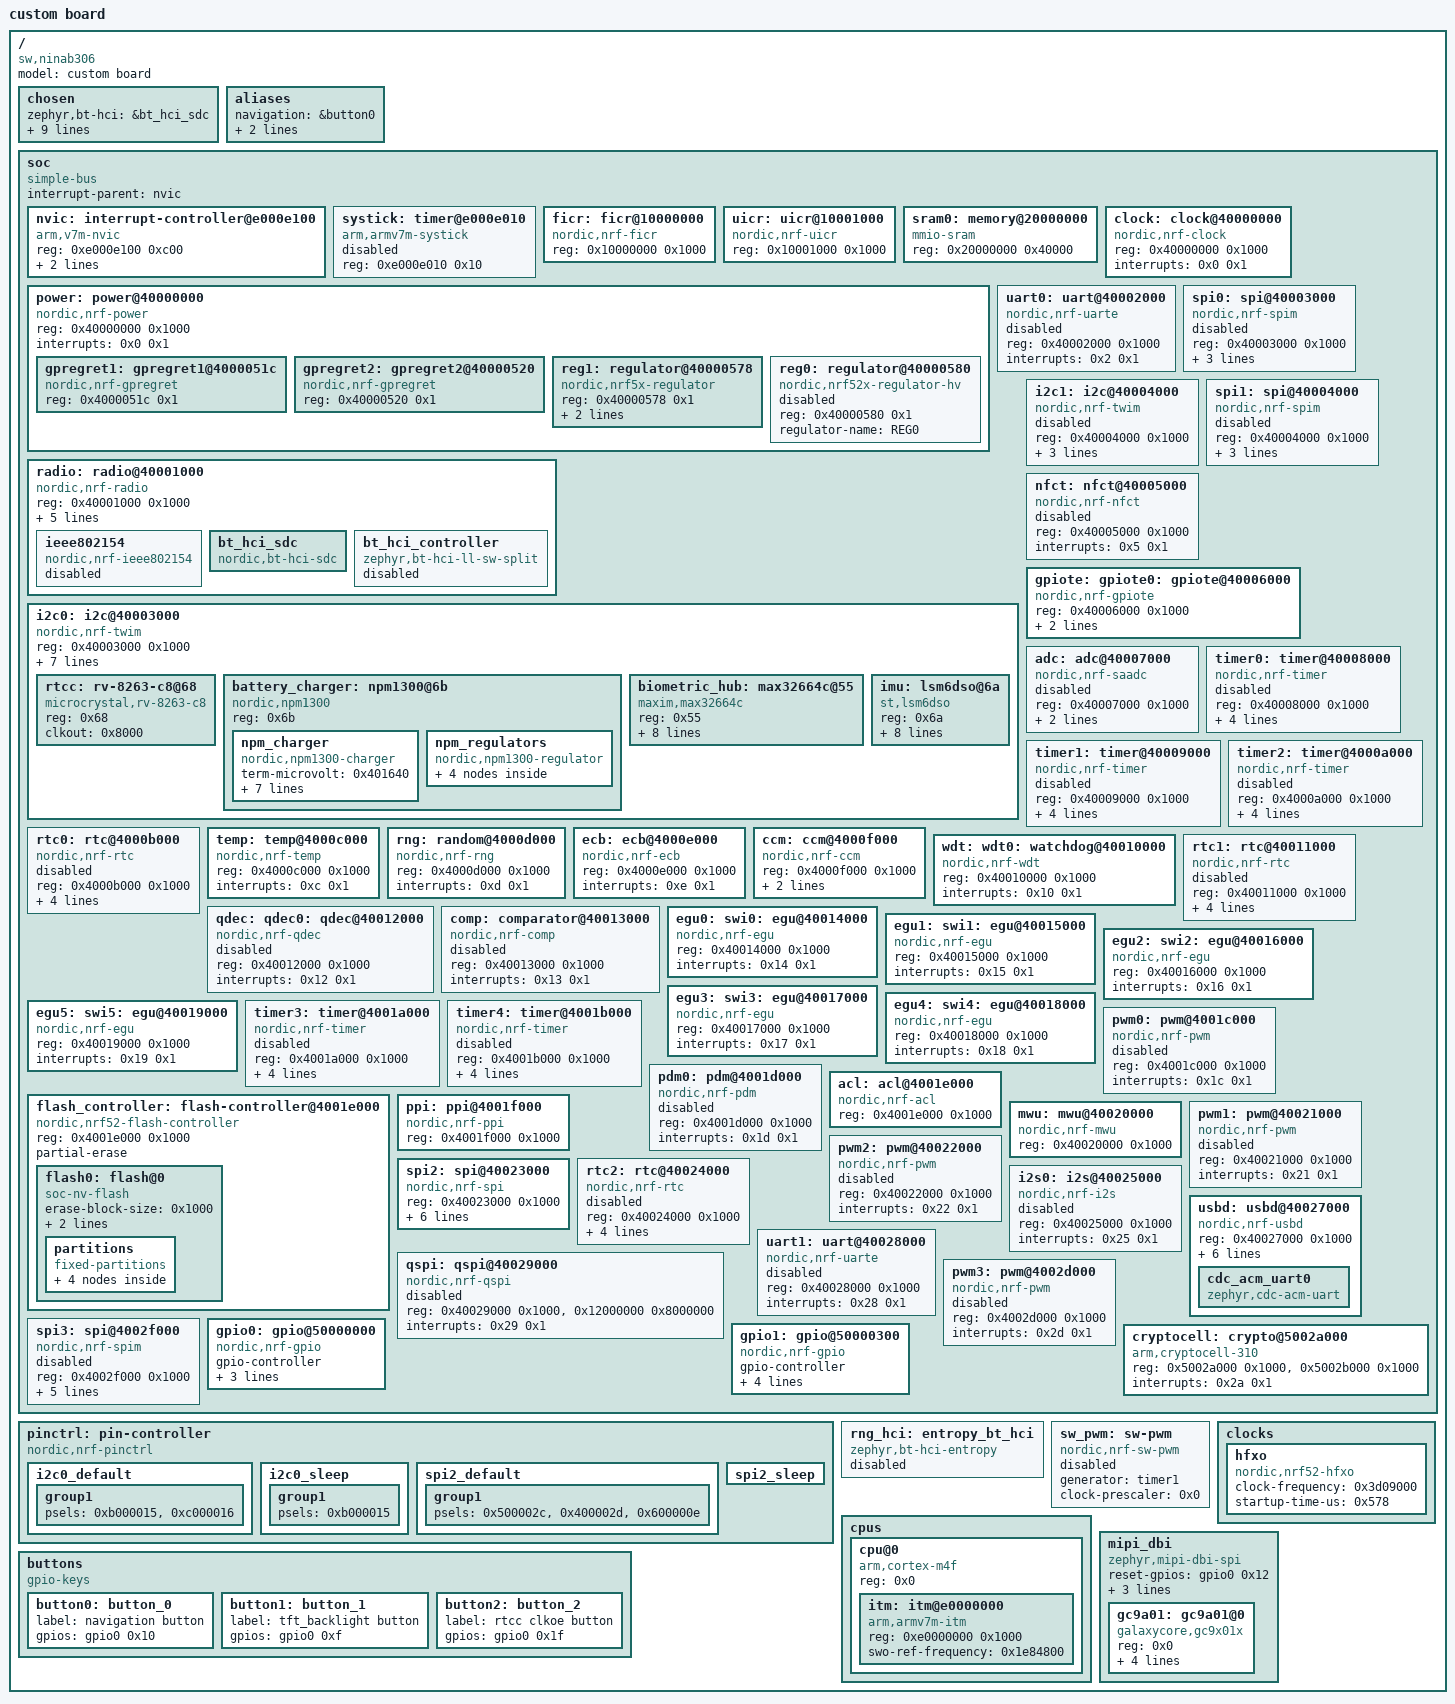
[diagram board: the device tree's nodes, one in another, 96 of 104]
/dts-v1/;

/* node '/' defined in zephyr/dts/common/skeleton.dtsi:9 */
/ {
	#address-cells = < 0x1 >;   /* in zephyr/dts/common/skeleton.dtsi:10 */
	#size-cells = < 0x1 >;      /* in zephyr/dts/common/skeleton.dtsi:11 */
	model = "custom board";     /* in ../../Documents/watch_project/nrf_firmware/boards/sw/ninab306/ninab306.dts:6 */
	compatible = "sw,ninab306"; /* in ../../Documents/watch_project/nrf_firmware/boards/sw/ninab306/ninab306.dts:7 */

	/* node '/chosen' defined in zephyr/dts/common/skeleton.dtsi:12 */
	chosen {
		zephyr,bt-hci = &bt_hci_sdc;                 /* in zephyr/dts/arm/nordic/nrf52840.dtsi:14 */
		zephyr,entropy = &cryptocell;                /* in zephyr/dts/arm/nordic/nrf52840.dtsi:15 */
		zephyr,flash-controller = &flash_controller; /* in zephyr/dts/arm/nordic/nrf52840.dtsi:16 */
		zephyr,sram = &sram0;                        /* in ../../Documents/watch_project/nrf_firmware/boards/sw/ninab306/ninab306.dts:10 */
		zephyr,flash = &flash0;                      /* in ../../Documents/watch_project/nrf_firmware/boards/sw/ninab306/ninab306.dts:11 */
		zephyr,code-partition = &slot0_partition;    /* in ../../Documents/watch_project/nrf_firmware/boards/sw/ninab306/ninab306.dts:12 */
		zephyr,console = &cdc_acm_uart0;             /* in ../../Documents/watch_project/nrf_firmware/boards/sw/ninab306/ninab306.dts:13 */
		zephyr,shell-uart = &cdc_acm_uart0;          /* in ../../Documents/watch_project/nrf_firmware/boards/sw/ninab306/ninab306.dts:14 */
		zephyr,bt-uart = &cdc_acm_uart0;             /* in ../../Documents/watch_project/nrf_firmware/boards/sw/ninab306/ninab306.dts:15 */
		zephyr,display = &gc9a01;                    /* in ../../Documents/watch_project/firmware/ninab306_nrf52840.overlay:18 */
	};

	/* node '/aliases' defined in zephyr/dts/common/skeleton.dtsi:13 */
	aliases {
		navigation = &button0; /* in ../../Documents/watch_project/firmware/ninab306_nrf52840.overlay:50 */
		bcklight = &button1;   /* in ../../Documents/watch_project/firmware/ninab306_nrf52840.overlay:51 */
		clkoe = &button2;      /* in ../../Documents/watch_project/firmware/ninab306_nrf52840.overlay:52 */
	};

	/* node '/soc' defined in zephyr/dts/arm/armv7-m.dtsi:6 */
	soc {
		#address-cells = < 0x1 >;     /* in zephyr/dts/arm/armv7-m.dtsi:7 */
		#size-cells = < 0x1 >;        /* in zephyr/dts/arm/armv7-m.dtsi:8 */
		interrupt-parent = < &nvic >; /* in zephyr/dts/arm/armv7-m.dtsi:10 */
		ranges;                       /* in zephyr/dts/arm/armv7-m.dtsi:11 */
		compatible = "simple-bus";    /* in zephyr/dts/arm/nordic/nrf52840_qiaa.dtsi:29 */

		/* node '/soc/interrupt-controller@e000e100' defined in zephyr/dts/arm/armv7-m.dtsi:13 */
		nvic: interrupt-controller@e000e100 {
			#address-cells = < 0x1 >;            /* in zephyr/dts/arm/armv7-m.dtsi:14 */
			compatible = "arm,v7m-nvic";         /* in zephyr/dts/arm/armv7-m.dtsi:15 */
			reg = < 0xe000e100 0xc00 >;          /* in zephyr/dts/arm/armv7-m.dtsi:16 */
			interrupt-controller;                /* in zephyr/dts/arm/armv7-m.dtsi:17 */
			#interrupt-cells = < 0x2 >;          /* in zephyr/dts/arm/armv7-m.dtsi:18 */
			arm,num-irq-priority-bits = < 0x3 >; /* in zephyr/dts/arm/nordic/nrf52840.dtsi:585 */
			phandle = < 0x1 >;                   /* in zephyr/dts/arm/armv7-m.dtsi:10 */
		};

		/* node '/soc/timer@e000e010' defined in zephyr/dts/arm/armv7-m.dtsi:21 */
		systick: timer@e000e010 {
			compatible = "arm,armv7m-systick"; /* in zephyr/dts/arm/armv7-m.dtsi:22 */
			reg = < 0xe000e010 0x10 >;         /* in zephyr/dts/arm/armv7-m.dtsi:23 */
			status = "disabled";               /* in zephyr/dts/arm/nordic/nrf52840.dtsi:590 */
		};

		/* node '/soc/ficr@10000000' defined in zephyr/dts/arm/nordic/nrf52840.dtsi:48 */
		ficr: ficr@10000000 {
			compatible = "nordic,nrf-ficr"; /* in zephyr/dts/arm/nordic/nrf52840.dtsi:49 */
			reg = < 0x10000000 0x1000 >;    /* in zephyr/dts/arm/nordic/nrf52840.dtsi:50 */
			#nordic,ficr-cells = < 0x1 >;   /* in zephyr/dts/arm/nordic/nrf52840.dtsi:51 */
			status = "okay";                /* in zephyr/dts/arm/nordic/nrf52840.dtsi:52 */
		};

		/* node '/soc/uicr@10001000' defined in zephyr/dts/arm/nordic/nrf52840.dtsi:55 */
		uicr: uicr@10001000 {
			compatible = "nordic,nrf-uicr"; /* in zephyr/dts/arm/nordic/nrf52840.dtsi:56 */
			reg = < 0x10001000 0x1000 >;    /* in zephyr/dts/arm/nordic/nrf52840.dtsi:57 */
			status = "okay";                /* in zephyr/dts/arm/nordic/nrf52840.dtsi:58 */
		};

		/* node '/soc/memory@20000000' defined in zephyr/dts/arm/nordic/nrf52840.dtsi:61 */
		sram0: memory@20000000 {
			compatible = "mmio-sram";     /* in zephyr/dts/arm/nordic/nrf52840.dtsi:62 */
			reg = < 0x20000000 0x40000 >; /* in zephyr/dts/arm/nordic/nrf52840_qiaa.dtsi:15 */
		};

		/* node '/soc/clock@40000000' defined in zephyr/dts/arm/nordic/nrf52840.dtsi:65 */
		clock: clock@40000000 {
			compatible = "nordic,nrf-clock"; /* in zephyr/dts/arm/nordic/nrf52840.dtsi:66 */
			reg = < 0x40000000 0x1000 >;     /* in zephyr/dts/arm/nordic/nrf52840.dtsi:67 */
			interrupts = < 0x0 0x1 >;        /* in zephyr/dts/arm/nordic/nrf52840.dtsi:68 */
			status = "okay";                 /* in zephyr/dts/arm/nordic/nrf52840.dtsi:69 */
		};

		/* node '/soc/power@40000000' defined in zephyr/dts/arm/nordic/nrf52840.dtsi:72 */
		power: power@40000000 {
			compatible = "nordic,nrf-power"; /* in zephyr/dts/arm/nordic/nrf52840.dtsi:73 */
			reg = < 0x40000000 0x1000 >;     /* in zephyr/dts/arm/nordic/nrf52840.dtsi:74 */
			interrupts = < 0x0 0x1 >;        /* in zephyr/dts/arm/nordic/nrf52840.dtsi:75 */
			status = "okay";                 /* in zephyr/dts/arm/nordic/nrf52840.dtsi:76 */
			#address-cells = < 0x1 >;        /* in zephyr/dts/arm/nordic/nrf52840.dtsi:77 */
			#size-cells = < 0x1 >;           /* in zephyr/dts/arm/nordic/nrf52840.dtsi:78 */

			/* node '/soc/power@40000000/gpregret1@4000051c' defined in zephyr/dts/arm/nordic/nrf52840.dtsi:80 */
			gpregret1: gpregret1@4000051c {
				#address-cells = < 0x1 >;           /* in zephyr/dts/arm/nordic/nrf52840.dtsi:81 */
				#size-cells = < 0x1 >;              /* in zephyr/dts/arm/nordic/nrf52840.dtsi:82 */
				compatible = "nordic,nrf-gpregret"; /* in zephyr/dts/arm/nordic/nrf52840.dtsi:83 */
				reg = < 0x4000051c 0x1 >;           /* in zephyr/dts/arm/nordic/nrf52840.dtsi:84 */
				status = "okay";                    /* in zephyr/dts/arm/nordic/nrf52840.dtsi:85 */
			};

			/* node '/soc/power@40000000/gpregret2@40000520' defined in zephyr/dts/arm/nordic/nrf52840.dtsi:88 */
			gpregret2: gpregret2@40000520 {
				#address-cells = < 0x1 >;           /* in zephyr/dts/arm/nordic/nrf52840.dtsi:89 */
				#size-cells = < 0x1 >;              /* in zephyr/dts/arm/nordic/nrf52840.dtsi:90 */
				compatible = "nordic,nrf-gpregret"; /* in zephyr/dts/arm/nordic/nrf52840.dtsi:91 */
				reg = < 0x40000520 0x1 >;           /* in zephyr/dts/arm/nordic/nrf52840.dtsi:92 */
				status = "okay";                    /* in zephyr/dts/arm/nordic/nrf52840.dtsi:93 */
			};

			/* node '/soc/power@40000000/regulator@40000578' defined in zephyr/dts/arm/nordic/nrf52840.dtsi:96 */
			reg1: regulator@40000578 {
				compatible = "nordic,nrf5x-regulator"; /* in zephyr/dts/arm/nordic/nrf52840.dtsi:97 */
				reg = < 0x40000578 0x1 >;              /* in zephyr/dts/arm/nordic/nrf52840.dtsi:98 */
				regulator-name = "REG1";               /* in zephyr/dts/arm/nordic/nrf52840.dtsi:99 */
				regulator-initial-mode = < 0x0 >;      /* in zephyr/dts/arm/nordic/nrf52840.dtsi:100 */
			};

			/* node '/soc/power@40000000/regulator@40000580' defined in zephyr/dts/arm/nordic/nrf52840_qiaa.dtsi:19 */
			reg0: regulator@40000580 {
				compatible = "nordic,nrf52x-regulator-hv"; /* in zephyr/dts/arm/nordic/nrf52840_qiaa.dtsi:20 */
				reg = < 0x40000580 0x1 >;                  /* in zephyr/dts/arm/nordic/nrf52840_qiaa.dtsi:21 */
				regulator-name = "REG0";                   /* in zephyr/dts/arm/nordic/nrf52840_qiaa.dtsi:22 */
				status = "disabled";                       /* in zephyr/dts/arm/nordic/nrf52840_qiaa.dtsi:23 */
			};
		};

		/* node '/soc/radio@40001000' defined in zephyr/dts/arm/nordic/nrf52840.dtsi:104 */
		radio: radio@40001000 {
			compatible = "nordic,nrf-radio"; /* in zephyr/dts/arm/nordic/nrf52840.dtsi:105 */
			reg = < 0x40001000 0x1000 >;     /* in zephyr/dts/arm/nordic/nrf52840.dtsi:106 */
			interrupts = < 0x1 0x1 >;        /* in zephyr/dts/arm/nordic/nrf52840.dtsi:107 */
			status = "okay";                 /* in zephyr/dts/arm/nordic/nrf52840.dtsi:108 */
			ieee802154-supported;            /* in zephyr/dts/arm/nordic/nrf52840.dtsi:109 */
			ble-2mbps-supported;             /* in zephyr/dts/arm/nordic/nrf52840.dtsi:110 */
			ble-coded-phy-supported;         /* in zephyr/dts/arm/nordic/nrf52840.dtsi:111 */
			tx-high-power-supported;         /* in zephyr/dts/arm/nordic/nrf52840.dtsi:112 */

			/* node '/soc/radio@40001000/ieee802154' defined in zephyr/dts/arm/nordic/nrf52840.dtsi:114 */
			ieee802154: ieee802154 {
				compatible = "nordic,nrf-ieee802154"; /* in zephyr/dts/arm/nordic/nrf52840.dtsi:115 */
				status = "disabled";                  /* in zephyr/dts/arm/nordic/nrf52840.dtsi:116 */
			};

			/* node '/soc/radio@40001000/bt_hci_sdc' defined in zephyr/dts/arm/nordic/nrf52840.dtsi:119 */
			bt_hci_sdc: bt_hci_sdc {
				compatible = "nordic,bt-hci-sdc"; /* in zephyr/dts/arm/nordic/nrf52840.dtsi:120 */
				status = "okay";                  /* in zephyr/dts/arm/nordic/nrf52840.dtsi:121 */
			};

			/* node '/soc/radio@40001000/bt_hci_controller' defined in zephyr/dts/arm/nordic/nrf52840.dtsi:123 */
			bt_hci_controller: bt_hci_controller {
				compatible = "zephyr,bt-hci-ll-sw-split"; /* in zephyr/dts/arm/nordic/nrf52840.dtsi:124 */
				status = "disabled";                      /* in zephyr/dts/arm/nordic/nrf52840.dtsi:125 */
			};
		};

		/* node '/soc/uart@40002000' defined in zephyr/dts/arm/nordic/nrf52840.dtsi:129 */
		uart0: uart@40002000 {
			compatible = "nordic,nrf-uarte"; /* in zephyr/dts/arm/nordic/nrf52840.dtsi:132 */
			reg = < 0x40002000 0x1000 >;     /* in zephyr/dts/arm/nordic/nrf52840.dtsi:133 */
			interrupts = < 0x2 0x1 >;        /* in zephyr/dts/arm/nordic/nrf52840.dtsi:134 */
			status = "disabled";             /* in zephyr/dts/arm/nordic/nrf52840.dtsi:135 */
		};

		/* node '/soc/i2c@40003000' defined in zephyr/dts/arm/nordic/nrf52840.dtsi:138 */
		i2c0: i2c@40003000 {
			compatible = "nordic,nrf-twim"; /* in zephyr/dts/arm/nordic/nrf52840.dtsi:146 */
			#address-cells = < 0x1 >;       /* in zephyr/dts/arm/nordic/nrf52840.dtsi:147 */
			#size-cells = < 0x0 >;          /* in zephyr/dts/arm/nordic/nrf52840.dtsi:148 */
			reg = < 0x40003000 0x1000 >;    /* in zephyr/dts/arm/nordic/nrf52840.dtsi:149 */
			interrupts = < 0x3 0x1 >;       /* in zephyr/dts/arm/nordic/nrf52840.dtsi:150 */
			easydma-maxcnt-bits = < 0x10 >; /* in zephyr/dts/arm/nordic/nrf52840.dtsi:151 */
			zephyr,pm-device-runtime-auto;  /* in zephyr/dts/arm/nordic/nrf52840.dtsi:153 */
			status = "okay";                /* in ../../Documents/watch_project/nrf_firmware/boards/sw/ninab306/ninab306.dts:66 */
			pinctrl-0 = < &i2c0_default >;  /* in ../../Documents/watch_project/nrf_firmware/boards/sw/ninab306/ninab306.dts:67 */
			pinctrl-1 = < &i2c0_sleep >;    /* in ../../Documents/watch_project/nrf_firmware/boards/sw/ninab306/ninab306.dts:68 */
			pinctrl-names = "default",
			                "sleep";        /* in ../../Documents/watch_project/nrf_firmware/boards/sw/ninab306/ninab306.dts:69 */
			clock-frequency = < 0x61a80 >;  /* in ../../Documents/watch_project/nrf_firmware/boards/sw/ninab306/ninab306.dts:70 */
			zephyr,deferred-init;           /* in ../../Documents/watch_project/nrf_firmware/boards/sw/ninab306/ninab306.dts:130 */

			/* node '/soc/i2c@40003000/rv-8263-c8@68' defined in ../../Documents/watch_project/nrf_firmware/boards/sw/ninab306/ninab306.dts:72 */
			rtcc: rv-8263-c8@68 {
				compatible = "microcrystal,rv-8263-c8"; /* in ../../Documents/watch_project/nrf_firmware/boards/sw/ninab306/ninab306.dts:73 */
				reg = < 0x68 >;                         /* in ../../Documents/watch_project/nrf_firmware/boards/sw/ninab306/ninab306.dts:74 */
				clkout = < 0x8000 >;                    /* in ../../Documents/watch_project/nrf_firmware/boards/sw/ninab306/ninab306.dts:75 */
				status = "okay";                        /* in ../../Documents/watch_project/nrf_firmware/boards/sw/ninab306/ninab306.dts:76 */
			};

			/* node '/soc/i2c@40003000/npm1300@6b' defined in ../../Documents/watch_project/nrf_firmware/boards/sw/ninab306/ninab306.dts:79 */
			battery_charger: npm1300@6b {
				compatible = "nordic,npm1300"; /* in ../../Documents/watch_project/nrf_firmware/boards/sw/ninab306/ninab306.dts:80 */
				reg = < 0x6b >;                /* in ../../Documents/watch_project/nrf_firmware/boards/sw/ninab306/ninab306.dts:81 */

				/* node '/soc/i2c@40003000/npm1300@6b/npm_charger' defined in ../../Documents/watch_project/nrf_firmware/boards/sw/ninab306/ninab306.dts:83 */
				npm_charger {
					compatible = "nordic,npm1300-charger"; /* in ../../Documents/watch_project/nrf_firmware/boards/sw/ninab306/ninab306.dts:84 */
					status = "okay";                       /* in ../../Documents/watch_project/nrf_firmware/boards/sw/ninab306/ninab306.dts:85 */
					term-microvolt = < 0x401640 >;         /* in ../../Documents/watch_project/nrf_firmware/boards/sw/ninab306/ninab306.dts:86 */
					current-microamp = < 0x7a120 >;        /* in ../../Documents/watch_project/nrf_firmware/boards/sw/ninab306/ninab306.dts:87 */
					dischg-limit-microamp = < 0xf4240 >;   /* in ../../Documents/watch_project/nrf_firmware/boards/sw/ninab306/ninab306.dts:88 */
					term-current-percent = < 0x14 >;       /* in ../../Documents/watch_project/nrf_firmware/boards/sw/ninab306/ninab306.dts:89 */
					vbus-limit-microamp = < 0x16e360 >;    /* in ../../Documents/watch_project/nrf_firmware/boards/sw/ninab306/ninab306.dts:90 */
					thermistor-ohms = < 0x0 >;             /* in ../../Documents/watch_project/nrf_firmware/boards/sw/ninab306/ninab306.dts:91 */
					thermistor-beta = < 0x0 >;             /* in ../../Documents/watch_project/nrf_firmware/boards/sw/ninab306/ninab306.dts:92 */
					charging-enable;                       /* in ../../Documents/watch_project/nrf_firmware/boards/sw/ninab306/ninab306.dts:93 */
				};

				/* node '/soc/i2c@40003000/npm1300@6b/npm_regulators' defined in ../../Documents/watch_project/nrf_firmware/boards/sw/ninab306/ninab306.dts:97 */
				npm_regulators {
					compatible = "nordic,npm1300-regulator"; /* in ../../Documents/watch_project/nrf_firmware/boards/sw/ninab306/ninab306.dts:98 */

					/* node '/soc/i2c@40003000/npm1300@6b/npm_regulators/BUCK1' defined in ../../Documents/watch_project/nrf_firmware/boards/sw/ninab306/ninab306.dts:100 */
					BUCK1 {
						regulator-boot-on; /* in ../../Documents/watch_project/nrf_firmware/boards/sw/ninab306/ninab306.dts:101 */
					};

					/* node '/soc/i2c@40003000/npm1300@6b/npm_regulators/BUCK2' defined in ../../Documents/watch_project/nrf_firmware/boards/sw/ninab306/ninab306.dts:104 */
					BUCK2 {
						regulator-boot-off; /* in ../../Documents/watch_project/nrf_firmware/boards/sw/ninab306/ninab306.dts:105 */
					};

					/* node '/soc/i2c@40003000/npm1300@6b/npm_regulators/LDO1' defined in ../../Documents/watch_project/nrf_firmware/boards/sw/ninab306/ninab306.dts:107 */
					LDO1 {
						regulator-boot-off; /* in ../../Documents/watch_project/nrf_firmware/boards/sw/ninab306/ninab306.dts:108 */
					};

					/* node '/soc/i2c@40003000/npm1300@6b/npm_regulators/LDO2' defined in ../../Documents/watch_project/nrf_firmware/boards/sw/ninab306/ninab306.dts:110 */
					LDO2 {
						regulator-boot-off; /* in ../../Documents/watch_project/nrf_firmware/boards/sw/ninab306/ninab306.dts:111 */
					};
				};
			};

			/* node '/soc/i2c@40003000/max32664c@55' defined in ../../Documents/watch_project/nrf_firmware/boards/sw/ninab306/ninab306.dts:116 */
			biometric_hub: max32664c@55 {
				compatible = "maxim,max32664c";    /* in ../../Documents/watch_project/nrf_firmware/boards/sw/ninab306/ninab306.dts:117 */
				reg = < 0x55 >;                    /* in ../../Documents/watch_project/nrf_firmware/boards/sw/ninab306/ninab306.dts:118 */
				status = "okay";                   /* in ../../Documents/watch_project/nrf_firmware/boards/sw/ninab306/ninab306.dts:119 */
				reset-gpios = < &gpio0 0x19 0x0 >; /* in ../../Documents/watch_project/nrf_firmware/boards/sw/ninab306/ninab306.dts:120 */
				mfio-gpios = < &gpio0 0x18 0x0 >;  /* in ../../Documents/watch_project/nrf_firmware/boards/sw/ninab306/ninab306.dts:121 */
				hr-config = [ 00 01 ];             /* in ../../Documents/watch_project/nrf_firmware/boards/sw/ninab306/ninab306.dts:122 */
				spo2-config = [ 11 21 ];           /* in ../../Documents/watch_project/nrf_firmware/boards/sw/ninab306/ninab306.dts:123 */
				led-current = [ 3F 3F 3F ];        /* in ../../Documents/watch_project/nrf_firmware/boards/sw/ninab306/ninab306.dts:124 */
				min-sampling-rate = < 0x190 >;     /* in ../../Documents/watch_project/nrf_firmware/boards/sw/ninab306/ninab306.dts:125 */
				max-sampling-rate = < 0x190 >;     /* in ../../Documents/watch_project/nrf_firmware/boards/sw/ninab306/ninab306.dts:126 */
				use-max86141;                      /* in ../../Documents/watch_project/nrf_firmware/boards/sw/ninab306/ninab306.dts:127 */
			};

			/* node '/soc/i2c@40003000/lsm6dso@6a' defined in ../../Documents/watch_project/nrf_firmware/boards/sw/ninab306/ninab306.dts:131 */
			imu: lsm6dso@6a {
				compatible = "st,lsm6dso"; /* in ../../Documents/watch_project/nrf_firmware/boards/sw/ninab306/ninab306.dts:132 */
				reg = < 0x6a >;            /* in ../../Documents/watch_project/nrf_firmware/boards/sw/ninab306/ninab306.dts:133 */
				drdy-pulsed;               /* in ../../Documents/watch_project/nrf_firmware/boards/sw/ninab306/ninab306.dts:134 */
				accel-odr = < 0x1 >;       /* in ../../Documents/watch_project/nrf_firmware/boards/sw/ninab306/ninab306.dts:135 */
				accel-pm = < 0x2 >;        /* in ../../Documents/watch_project/nrf_firmware/boards/sw/ninab306/ninab306.dts:136 */
				accel-range = < 0x3 >;     /* in ../../Documents/watch_project/nrf_firmware/boards/sw/ninab306/ninab306.dts:137 */
				gyro-odr = < 0x1 >;        /* in ../../Documents/watch_project/nrf_firmware/boards/sw/ninab306/ninab306.dts:138 */
				gyro-pm = < 0x1 >;         /* in ../../Documents/watch_project/nrf_firmware/boards/sw/ninab306/ninab306.dts:139 */
				gyro-range = < 0x6 >;      /* in ../../Documents/watch_project/nrf_firmware/boards/sw/ninab306/ninab306.dts:140 */
				int-pin = < 0x2 >;         /* in ../../Documents/watch_project/nrf_firmware/boards/sw/ninab306/ninab306.dts:141 */
				status = "okay";           /* in ../../Documents/watch_project/nrf_firmware/boards/sw/ninab306/ninab306.dts:142 */
			};
		};

		/* node '/soc/spi@40003000' defined in zephyr/dts/arm/nordic/nrf52840.dtsi:156 */
		spi0: spi@40003000 {
			compatible = "nordic,nrf-spim"; /* in zephyr/dts/arm/nordic/nrf52840.dtsi:164 */
			#address-cells = < 0x1 >;       /* in zephyr/dts/arm/nordic/nrf52840.dtsi:165 */
			#size-cells = < 0x0 >;          /* in zephyr/dts/arm/nordic/nrf52840.dtsi:166 */
			reg = < 0x40003000 0x1000 >;    /* in zephyr/dts/arm/nordic/nrf52840.dtsi:167 */
			interrupts = < 0x3 0x1 >;       /* in zephyr/dts/arm/nordic/nrf52840.dtsi:168 */
			max-frequency = < 0x7a1200 >;   /* in zephyr/dts/arm/nordic/nrf52840.dtsi:169 */
			easydma-maxcnt-bits = < 0x10 >; /* in zephyr/dts/arm/nordic/nrf52840.dtsi:170 */
			status = "disabled";            /* in zephyr/dts/arm/nordic/nrf52840.dtsi:171 */
		};

		/* node '/soc/i2c@40004000' defined in zephyr/dts/arm/nordic/nrf52840.dtsi:174 */
		i2c1: i2c@40004000 {
			compatible = "nordic,nrf-twim"; /* in zephyr/dts/arm/nordic/nrf52840.dtsi:182 */
			#address-cells = < 0x1 >;       /* in zephyr/dts/arm/nordic/nrf52840.dtsi:183 */
			#size-cells = < 0x0 >;          /* in zephyr/dts/arm/nordic/nrf52840.dtsi:184 */
			reg = < 0x40004000 0x1000 >;    /* in zephyr/dts/arm/nordic/nrf52840.dtsi:185 */
			interrupts = < 0x4 0x1 >;       /* in zephyr/dts/arm/nordic/nrf52840.dtsi:186 */
			easydma-maxcnt-bits = < 0x10 >; /* in zephyr/dts/arm/nordic/nrf52840.dtsi:187 */
			status = "disabled";            /* in zephyr/dts/arm/nordic/nrf52840.dtsi:188 */
			zephyr,pm-device-runtime-auto;  /* in zephyr/dts/arm/nordic/nrf52840.dtsi:189 */
		};

		/* node '/soc/spi@40004000' defined in zephyr/dts/arm/nordic/nrf52840.dtsi:192 */
		spi1: spi@40004000 {
			compatible = "nordic,nrf-spim"; /* in zephyr/dts/arm/nordic/nrf52840.dtsi:200 */
			#address-cells = < 0x1 >;       /* in zephyr/dts/arm/nordic/nrf52840.dtsi:201 */
			#size-cells = < 0x0 >;          /* in zephyr/dts/arm/nordic/nrf52840.dtsi:202 */
			reg = < 0x40004000 0x1000 >;    /* in zephyr/dts/arm/nordic/nrf52840.dtsi:203 */
			interrupts = < 0x4 0x1 >;       /* in zephyr/dts/arm/nordic/nrf52840.dtsi:204 */
			max-frequency = < 0x7a1200 >;   /* in zephyr/dts/arm/nordic/nrf52840.dtsi:205 */
			easydma-maxcnt-bits = < 0x10 >; /* in zephyr/dts/arm/nordic/nrf52840.dtsi:206 */
			status = "disabled";            /* in zephyr/dts/arm/nordic/nrf52840.dtsi:207 */
		};

		/* node '/soc/nfct@40005000' defined in zephyr/dts/arm/nordic/nrf52840.dtsi:210 */
		nfct: nfct@40005000 {
			compatible = "nordic,nrf-nfct"; /* in zephyr/dts/arm/nordic/nrf52840.dtsi:211 */
			reg = < 0x40005000 0x1000 >;    /* in zephyr/dts/arm/nordic/nrf52840.dtsi:212 */
			interrupts = < 0x5 0x1 >;       /* in zephyr/dts/arm/nordic/nrf52840.dtsi:213 */
			status = "disabled";            /* in zephyr/dts/arm/nordic/nrf52840.dtsi:214 */
		};

		/* node '/soc/gpiote@40006000' defined in zephyr/dts/arm/nordic/nrf52840.dtsi:217 */
		gpiote: gpiote0: gpiote@40006000 {
			compatible = "nordic,nrf-gpiote"; /* in zephyr/dts/arm/nordic/nrf52840.dtsi:218 */
			reg = < 0x40006000 0x1000 >;      /* in zephyr/dts/arm/nordic/nrf52840.dtsi:219 */
			interrupts = < 0x6 0x5 >;         /* in zephyr/dts/arm/nordic/nrf52840.dtsi:220 */
			instance = < 0x0 >;               /* in zephyr/dts/arm/nordic/nrf52840.dtsi:222 */
			status = "okay";                  /* in ../../Documents/watch_project/nrf_firmware/boards/sw/ninab306/ninab306.dts:151 */
			phandle = < 0x7 >;                /* in zephyr/dts/arm/nordic/nrf52840.dtsi:559 */
		};

		/* node '/soc/adc@40007000' defined in zephyr/dts/arm/nordic/nrf52840.dtsi:225 */
		adc: adc@40007000 {
			compatible = "nordic,nrf-saadc"; /* in zephyr/dts/arm/nordic/nrf52840.dtsi:226 */
			reg = < 0x40007000 0x1000 >;     /* in zephyr/dts/arm/nordic/nrf52840.dtsi:227 */
			interrupts = < 0x7 0x1 >;        /* in zephyr/dts/arm/nordic/nrf52840.dtsi:228 */
			status = "disabled";             /* in zephyr/dts/arm/nordic/nrf52840.dtsi:229 */
			#io-channel-cells = < 0x1 >;     /* in zephyr/dts/arm/nordic/nrf52840.dtsi:230 */
			zephyr,pm-device-runtime-auto;   /* in zephyr/dts/arm/nordic/nrf52840.dtsi:231 */
		};

		/* node '/soc/timer@40008000' defined in zephyr/dts/arm/nordic/nrf52840.dtsi:234 */
		timer0: timer@40008000 {
			compatible = "nordic,nrf-timer"; /* in zephyr/dts/arm/nordic/nrf52840.dtsi:235 */
			status = "disabled";             /* in zephyr/dts/arm/nordic/nrf52840.dtsi:236 */
			reg = < 0x40008000 0x1000 >;     /* in zephyr/dts/arm/nordic/nrf52840.dtsi:237 */
			cc-num = < 0x4 >;                /* in zephyr/dts/arm/nordic/nrf52840.dtsi:238 */
			max-bit-width = < 0x20 >;        /* in zephyr/dts/arm/nordic/nrf52840.dtsi:239 */
			interrupts = < 0x8 0x1 >;        /* in zephyr/dts/arm/nordic/nrf52840.dtsi:240 */
			prescaler = < 0x0 >;             /* in zephyr/dts/arm/nordic/nrf52840.dtsi:241 */
		};

		/* node '/soc/timer@40009000' defined in zephyr/dts/arm/nordic/nrf52840.dtsi:244 */
		timer1: timer@40009000 {
			compatible = "nordic,nrf-timer"; /* in zephyr/dts/arm/nordic/nrf52840.dtsi:245 */
			status = "disabled";             /* in zephyr/dts/arm/nordic/nrf52840.dtsi:246 */
			reg = < 0x40009000 0x1000 >;     /* in zephyr/dts/arm/nordic/nrf52840.dtsi:247 */
			cc-num = < 0x4 >;                /* in zephyr/dts/arm/nordic/nrf52840.dtsi:248 */
			max-bit-width = < 0x20 >;        /* in zephyr/dts/arm/nordic/nrf52840.dtsi:249 */
			interrupts = < 0x9 0x1 >;        /* in zephyr/dts/arm/nordic/nrf52840.dtsi:250 */
			prescaler = < 0x0 >;             /* in zephyr/dts/arm/nordic/nrf52840.dtsi:251 */
			phandle = < 0x8 >;               /* in zephyr/dts/vendor/nordic/nrf_common.dtsi:42 */
		};

		/* node '/soc/timer@4000a000' defined in zephyr/dts/arm/nordic/nrf52840.dtsi:254 */
		timer2: timer@4000a000 {
			compatible = "nordic,nrf-timer"; /* in zephyr/dts/arm/nordic/nrf52840.dtsi:255 */
			status = "disabled";             /* in zephyr/dts/arm/nordic/nrf52840.dtsi:256 */
			reg = < 0x4000a000 0x1000 >;     /* in zephyr/dts/arm/nordic/nrf52840.dtsi:257 */
			cc-num = < 0x4 >;                /* in zephyr/dts/arm/nordic/nrf52840.dtsi:258 */
			max-bit-width = < 0x20 >;        /* in zephyr/dts/arm/nordic/nrf52840.dtsi:259 */
			interrupts = < 0xa 0x1 >;        /* in zephyr/dts/arm/nordic/nrf52840.dtsi:260 */
			prescaler = < 0x0 >;             /* in zephyr/dts/arm/nordic/nrf52840.dtsi:261 */
		};

		/* node '/soc/rtc@4000b000' defined in zephyr/dts/arm/nordic/nrf52840.dtsi:264 */
		rtc0: rtc@4000b000 {
			compatible = "nordic,nrf-rtc"; /* in zephyr/dts/arm/nordic/nrf52840.dtsi:265 */
			reg = < 0x4000b000 0x1000 >;   /* in zephyr/dts/arm/nordic/nrf52840.dtsi:266 */
			cc-num = < 0x3 >;              /* in zephyr/dts/arm/nordic/nrf52840.dtsi:267 */
			interrupts = < 0xb 0x1 >;      /* in zephyr/dts/arm/nordic/nrf52840.dtsi:268 */
			status = "disabled";           /* in zephyr/dts/arm/nordic/nrf52840.dtsi:269 */
			clock-frequency = < 0x8000 >;  /* in zephyr/dts/arm/nordic/nrf52840.dtsi:270 */
			prescaler = < 0x1 >;           /* in zephyr/dts/arm/nordic/nrf52840.dtsi:271 */
		};

		/* node '/soc/temp@4000c000' defined in zephyr/dts/arm/nordic/nrf52840.dtsi:274 */
		temp: temp@4000c000 {
			compatible = "nordic,nrf-temp"; /* in zephyr/dts/arm/nordic/nrf52840.dtsi:275 */
			reg = < 0x4000c000 0x1000 >;    /* in zephyr/dts/arm/nordic/nrf52840.dtsi:276 */
			interrupts = < 0xc 0x1 >;       /* in zephyr/dts/arm/nordic/nrf52840.dtsi:277 */
			status = "okay";                /* in zephyr/dts/arm/nordic/nrf52840.dtsi:278 */
		};

		/* node '/soc/random@4000d000' defined in zephyr/dts/arm/nordic/nrf52840.dtsi:281 */
		rng: random@4000d000 {
			compatible = "nordic,nrf-rng"; /* in zephyr/dts/arm/nordic/nrf52840.dtsi:282 */
			reg = < 0x4000d000 0x1000 >;   /* in zephyr/dts/arm/nordic/nrf52840.dtsi:283 */
			interrupts = < 0xd 0x1 >;      /* in zephyr/dts/arm/nordic/nrf52840.dtsi:284 */
			status = "okay";               /* in zephyr/dts/arm/nordic/nrf52840.dtsi:285 */
		};

		/* node '/soc/ecb@4000e000' defined in zephyr/dts/arm/nordic/nrf52840.dtsi:288 */
		ecb: ecb@4000e000 {
			compatible = "nordic,nrf-ecb"; /* in zephyr/dts/arm/nordic/nrf52840.dtsi:289 */
			reg = < 0x4000e000 0x1000 >;   /* in zephyr/dts/arm/nordic/nrf52840.dtsi:290 */
			interrupts = < 0xe 0x1 >;      /* in zephyr/dts/arm/nordic/nrf52840.dtsi:291 */
			status = "okay";               /* in zephyr/dts/arm/nordic/nrf52840.dtsi:292 */
		};

		/* node '/soc/ccm@4000f000' defined in zephyr/dts/arm/nordic/nrf52840.dtsi:295 */
		ccm: ccm@4000f000 {
			compatible = "nordic,nrf-ccm"; /* in zephyr/dts/arm/nordic/nrf52840.dtsi:296 */
			reg = < 0x4000f000 0x1000 >;   /* in zephyr/dts/arm/nordic/nrf52840.dtsi:297 */
			interrupts = < 0xf 0x1 >;      /* in zephyr/dts/arm/nordic/nrf52840.dtsi:298 */
			length-field-length-8-bits;    /* in zephyr/dts/arm/nordic/nrf52840.dtsi:299 */
			status = "okay";               /* in zephyr/dts/arm/nordic/nrf52840.dtsi:300 */
		};

		/* node '/soc/watchdog@40010000' defined in zephyr/dts/arm/nordic/nrf52840.dtsi:303 */
		wdt: wdt0: watchdog@40010000 {
			compatible = "nordic,nrf-wdt"; /* in zephyr/dts/arm/nordic/nrf52840.dtsi:304 */
			reg = < 0x40010000 0x1000 >;   /* in zephyr/dts/arm/nordic/nrf52840.dtsi:305 */
			interrupts = < 0x10 0x1 >;     /* in zephyr/dts/arm/nordic/nrf52840.dtsi:306 */
			status = "okay";               /* in zephyr/dts/arm/nordic/nrf52840.dtsi:307 */
		};

		/* node '/soc/rtc@40011000' defined in zephyr/dts/arm/nordic/nrf52840.dtsi:310 */
		rtc1: rtc@40011000 {
			compatible = "nordic,nrf-rtc"; /* in zephyr/dts/arm/nordic/nrf52840.dtsi:311 */
			reg = < 0x40011000 0x1000 >;   /* in zephyr/dts/arm/nordic/nrf52840.dtsi:312 */
			cc-num = < 0x4 >;              /* in zephyr/dts/arm/nordic/nrf52840.dtsi:313 */
			interrupts = < 0x11 0x1 >;     /* in zephyr/dts/arm/nordic/nrf52840.dtsi:314 */
			status = "disabled";           /* in zephyr/dts/arm/nordic/nrf52840.dtsi:315 */
			clock-frequency = < 0x8000 >;  /* in zephyr/dts/arm/nordic/nrf52840.dtsi:316 */
			prescaler = < 0x1 >;           /* in zephyr/dts/arm/nordic/nrf52840.dtsi:317 */
		};

		/* node '/soc/qdec@40012000' defined in zephyr/dts/arm/nordic/nrf52840.dtsi:320 */
		qdec: qdec0: qdec@40012000 {
			compatible = "nordic,nrf-qdec"; /* in zephyr/dts/arm/nordic/nrf52840.dtsi:321 */
			reg = < 0x40012000 0x1000 >;    /* in zephyr/dts/arm/nordic/nrf52840.dtsi:322 */
			interrupts = < 0x12 0x1 >;      /* in zephyr/dts/arm/nordic/nrf52840.dtsi:323 */
			status = "disabled";            /* in zephyr/dts/arm/nordic/nrf52840.dtsi:324 */
		};

		/* node '/soc/comparator@40013000' defined in zephyr/dts/arm/nordic/nrf52840.dtsi:327 */
		comp: comparator@40013000 {
			compatible = "nordic,nrf-comp"; /* in zephyr/dts/arm/nordic/nrf52840.dtsi:332 */
			reg = < 0x40013000 0x1000 >;    /* in zephyr/dts/arm/nordic/nrf52840.dtsi:333 */
			interrupts = < 0x13 0x1 >;      /* in zephyr/dts/arm/nordic/nrf52840.dtsi:334 */
			status = "disabled";            /* in zephyr/dts/arm/nordic/nrf52840.dtsi:335 */
		};

		/* node '/soc/egu@40014000' defined in zephyr/dts/arm/nordic/nrf52840.dtsi:338 */
		egu0: swi0: egu@40014000 {
			compatible = "nordic,nrf-egu",
			             "nordic,nrf-swi"; /* in zephyr/dts/arm/nordic/nrf52840.dtsi:339 */
			reg = < 0x40014000 0x1000 >;   /* in zephyr/dts/arm/nordic/nrf52840.dtsi:340 */
			interrupts = < 0x14 0x1 >;     /* in zephyr/dts/arm/nordic/nrf52840.dtsi:341 */
			status = "okay";               /* in zephyr/dts/arm/nordic/nrf52840.dtsi:342 */
		};

		/* node '/soc/egu@40015000' defined in zephyr/dts/arm/nordic/nrf52840.dtsi:345 */
		egu1: swi1: egu@40015000 {
			compatible = "nordic,nrf-egu",
			             "nordic,nrf-swi"; /* in zephyr/dts/arm/nordic/nrf52840.dtsi:346 */
			reg = < 0x40015000 0x1000 >;   /* in zephyr/dts/arm/nordic/nrf52840.dtsi:347 */
			interrupts = < 0x15 0x1 >;     /* in zephyr/dts/arm/nordic/nrf52840.dtsi:348 */
			status = "okay";               /* in zephyr/dts/arm/nordic/nrf52840.dtsi:349 */
		};

		/* node '/soc/egu@40016000' defined in zephyr/dts/arm/nordic/nrf52840.dtsi:352 */
		egu2: swi2: egu@40016000 {
			compatible = "nordic,nrf-egu",
			             "nordic,nrf-swi"; /* in zephyr/dts/arm/nordic/nrf52840.dtsi:353 */
			reg = < 0x40016000 0x1000 >;   /* in zephyr/dts/arm/nordic/nrf52840.dtsi:354 */
			interrupts = < 0x16 0x1 >;     /* in zephyr/dts/arm/nordic/nrf52840.dtsi:355 */
			status = "okay";               /* in zephyr/dts/arm/nordic/nrf52840.dtsi:356 */
		};

		/* node '/soc/egu@40017000' defined in zephyr/dts/arm/nordic/nrf52840.dtsi:359 */
		egu3: swi3: egu@40017000 {
			compatible = "nordic,nrf-egu",
			             "nordic,nrf-swi"; /* in zephyr/dts/arm/nordic/nrf52840.dtsi:360 */
			reg = < 0x40017000 0x1000 >;   /* in zephyr/dts/arm/nordic/nrf52840.dtsi:361 */
			interrupts = < 0x17 0x1 >;     /* in zephyr/dts/arm/nordic/nrf52840.dtsi:362 */
			status = "okay";               /* in zephyr/dts/arm/nordic/nrf52840.dtsi:363 */
		};

		/* node '/soc/egu@40018000' defined in zephyr/dts/arm/nordic/nrf52840.dtsi:366 */
		egu4: swi4: egu@40018000 {
			compatible = "nordic,nrf-egu",
			             "nordic,nrf-swi"; /* in zephyr/dts/arm/nordic/nrf52840.dtsi:367 */
			reg = < 0x40018000 0x1000 >;   /* in zephyr/dts/arm/nordic/nrf52840.dtsi:368 */
			interrupts = < 0x18 0x1 >;     /* in zephyr/dts/arm/nordic/nrf52840.dtsi:369 */
			status = "okay";               /* in zephyr/dts/arm/nordic/nrf52840.dtsi:370 */
		};

		/* node '/soc/egu@40019000' defined in zephyr/dts/arm/nordic/nrf52840.dtsi:373 */
		egu5: swi5: egu@40019000 {
			compatible = "nordic,nrf-egu",
			             "nordic,nrf-swi"; /* in zephyr/dts/arm/nordic/nrf52840.dtsi:374 */
			reg = < 0x40019000 0x1000 >;   /* in zephyr/dts/arm/nordic/nrf52840.dtsi:375 */
			interrupts = < 0x19 0x1 >;     /* in zephyr/dts/arm/nordic/nrf52840.dtsi:376 */
			status = "okay";               /* in zephyr/dts/arm/nordic/nrf52840.dtsi:377 */
		};

		/* node '/soc/timer@4001a000' defined in zephyr/dts/arm/nordic/nrf52840.dtsi:380 */
		timer3: timer@4001a000 {
			compatible = "nordic,nrf-timer"; /* in zephyr/dts/arm/nordic/nrf52840.dtsi:381 */
			status = "disabled";             /* in zephyr/dts/arm/nordic/nrf52840.dtsi:382 */
			reg = < 0x4001a000 0x1000 >;     /* in zephyr/dts/arm/nordic/nrf52840.dtsi:383 */
			cc-num = < 0x6 >;                /* in zephyr/dts/arm/nordic/nrf52840.dtsi:384 */
			max-bit-width = < 0x20 >;        /* in zephyr/dts/arm/nordic/nrf52840.dtsi:385 */
			interrupts = < 0x1a 0x1 >;       /* in zephyr/dts/arm/nordic/nrf52840.dtsi:386 */
			prescaler = < 0x0 >;             /* in zephyr/dts/arm/nordic/nrf52840.dtsi:387 */
		};

		/* node '/soc/timer@4001b000' defined in zephyr/dts/arm/nordic/nrf52840.dtsi:390 */
		timer4: timer@4001b000 {
			compatible = "nordic,nrf-timer"; /* in zephyr/dts/arm/nordic/nrf52840.dtsi:391 */
			status = "disabled";             /* in zephyr/dts/arm/nordic/nrf52840.dtsi:392 */
			reg = < 0x4001b000 0x1000 >;     /* in zephyr/dts/arm/nordic/nrf52840.dtsi:393 */
			cc-num = < 0x6 >;                /* in zephyr/dts/arm/nordic/nrf52840.dtsi:394 */
			max-bit-width = < 0x20 >;        /* in zephyr/dts/arm/nordic/nrf52840.dtsi:395 */
			interrupts = < 0x1b 0x1 >;       /* in zephyr/dts/arm/nordic/nrf52840.dtsi:396 */
			prescaler = < 0x0 >;             /* in zephyr/dts/arm/nordic/nrf52840.dtsi:397 */
		};

		/* node '/soc/pwm@4001c000' defined in zephyr/dts/arm/nordic/nrf52840.dtsi:400 */
		pwm0: pwm@4001c000 {
			compatible = "nordic,nrf-pwm"; /* in zephyr/dts/arm/nordic/nrf52840.dtsi:401 */
			reg = < 0x4001c000 0x1000 >;   /* in zephyr/dts/arm/nordic/nrf52840.dtsi:402 */
			interrupts = < 0x1c 0x1 >;     /* in zephyr/dts/arm/nordic/nrf52840.dtsi:403 */
			status = "disabled";           /* in zephyr/dts/arm/nordic/nrf52840.dtsi:404 */
			#pwm-cells = < 0x3 >;          /* in zephyr/dts/arm/nordic/nrf52840.dtsi:405 */
		};

		/* node '/soc/pdm@4001d000' defined in zephyr/dts/arm/nordic/nrf52840.dtsi:408 */
		pdm0: pdm@4001d000 {
			compatible = "nordic,nrf-pdm"; /* in zephyr/dts/arm/nordic/nrf52840.dtsi:409 */
			reg = < 0x4001d000 0x1000 >;   /* in zephyr/dts/arm/nordic/nrf52840.dtsi:410 */
			interrupts = < 0x1d 0x1 >;     /* in zephyr/dts/arm/nordic/nrf52840.dtsi:411 */
			status = "disabled";           /* in zephyr/dts/arm/nordic/nrf52840.dtsi:412 */
		};

		/* node '/soc/acl@4001e000' defined in zephyr/dts/arm/nordic/nrf52840.dtsi:415 */
		acl: acl@4001e000 {
			compatible = "nordic,nrf-acl"; /* in zephyr/dts/arm/nordic/nrf52840.dtsi:416 */
			reg = < 0x4001e000 0x1000 >;   /* in zephyr/dts/arm/nordic/nrf52840.dtsi:417 */
			status = "okay";               /* in zephyr/dts/arm/nordic/nrf52840.dtsi:418 */
		};

		/* node '/soc/flash-controller@4001e000' defined in zephyr/dts/arm/nordic/nrf52840.dtsi:421 */
		flash_controller: flash-controller@4001e000 {
			compatible = "nordic,nrf52-flash-controller"; /* in zephyr/dts/arm/nordic/nrf52840.dtsi:422 */
			reg = < 0x4001e000 0x1000 >;                  /* in zephyr/dts/arm/nordic/nrf52840.dtsi:423 */
			partial-erase;                                /* in zephyr/dts/arm/nordic/nrf52840.dtsi:424 */
			#address-cells = < 0x1 >;                     /* in zephyr/dts/arm/nordic/nrf52840.dtsi:426 */
			#size-cells = < 0x1 >;                        /* in zephyr/dts/arm/nordic/nrf52840.dtsi:427 */

			/* node '/soc/flash-controller@4001e000/flash@0' defined in zephyr/dts/arm/nordic/nrf52840.dtsi:429 */
			flash0: flash@0 {
				compatible = "soc-nv-flash";   /* in zephyr/dts/arm/nordic/nrf52840.dtsi:430 */
				erase-block-size = < 0x1000 >; /* in zephyr/dts/arm/nordic/nrf52840.dtsi:431 */
				write-block-size = < 0x4 >;    /* in zephyr/dts/arm/nordic/nrf52840.dtsi:432 */
				reg = < 0x0 0x100000 >;        /* in zephyr/dts/arm/nordic/nrf52840_qiaa.dtsi:11 */

				/* node '/soc/flash-controller@4001e000/flash@0/partitions' defined in ../../Documents/watch_project/nrf_firmware/boards/sw/ninab306/ninab306.dts:38 */
				partitions {
					compatible = "fixed-partitions"; /* in ../../Documents/watch_project/nrf_firmware/boards/sw/ninab306/ninab306.dts:39 */
					#address-cells = < 0x1 >;        /* in ../../Documents/watch_project/nrf_firmware/boards/sw/ninab306/ninab306.dts:40 */
					#size-cells = < 0x1 >;           /* in ../../Documents/watch_project/nrf_firmware/boards/sw/ninab306/ninab306.dts:41 */

					/* node '/soc/flash-controller@4001e000/flash@0/partitions/partition@0' defined in ../../Documents/watch_project/nrf_firmware/boards/sw/ninab306/ninab306.dts:43 */
					boot_partition: partition@0 {
						label = "mcuboot";    /* in ../../Documents/watch_project/nrf_firmware/boards/sw/ninab306/ninab306.dts:44 */
						reg = < 0x0 0xc000 >; /* in ../../Documents/watch_project/nrf_firmware/boards/sw/ninab306/ninab306.dts:45 */
					};

					/* node '/soc/flash-controller@4001e000/flash@0/partitions/partition@c000' defined in ../../Documents/watch_project/nrf_firmware/boards/sw/ninab306/ninab306.dts:48 */
					slot0_partition: partition@c000 {
						label = "image-0";        /* in ../../Documents/watch_project/nrf_firmware/boards/sw/ninab306/ninab306.dts:49 */
						reg = < 0xc000 0x76000 >; /* in ../../Documents/watch_project/nrf_firmware/boards/sw/ninab306/ninab306.dts:50 */
					};

					/* node '/soc/flash-controller@4001e000/flash@0/partitions/partition@82000' defined in ../../Documents/watch_project/nrf_firmware/boards/sw/ninab306/ninab306.dts:53 */
					slot1_partition: partition@82000 {
						label = "image-1";         /* in ../../Documents/watch_project/nrf_firmware/boards/sw/ninab306/ninab306.dts:54 */
						reg = < 0x82000 0x76000 >; /* in ../../Documents/watch_project/nrf_firmware/boards/sw/ninab306/ninab306.dts:55 */
					};

					/* node '/soc/flash-controller@4001e000/flash@0/partitions/partition@f8000' defined in ../../Documents/watch_project/nrf_firmware/boards/sw/ninab306/ninab306.dts:58 */
					storage_partition: partition@f8000 {
						label = "storage";        /* in ../../Documents/watch_project/nrf_firmware/boards/sw/ninab306/ninab306.dts:59 */
						reg = < 0xf8000 0x8000 >; /* in ../../Documents/watch_project/nrf_firmware/boards/sw/ninab306/ninab306.dts:60 */
					};
				};
			};
		};

		/* node '/soc/ppi@4001f000' defined in zephyr/dts/arm/nordic/nrf52840.dtsi:436 */
		ppi: ppi@4001f000 {
			compatible = "nordic,nrf-ppi"; /* in zephyr/dts/arm/nordic/nrf52840.dtsi:437 */
			reg = < 0x4001f000 0x1000 >;   /* in zephyr/dts/arm/nordic/nrf52840.dtsi:438 */
			status = "okay";               /* in zephyr/dts/arm/nordic/nrf52840.dtsi:439 */
		};

		/* node '/soc/mwu@40020000' defined in zephyr/dts/arm/nordic/nrf52840.dtsi:442 */
		mwu: mwu@40020000 {
			compatible = "nordic,nrf-mwu"; /* in zephyr/dts/arm/nordic/nrf52840.dtsi:443 */
			reg = < 0x40020000 0x1000 >;   /* in zephyr/dts/arm/nordic/nrf52840.dtsi:444 */
			status = "okay";               /* in zephyr/dts/arm/nordic/nrf52840.dtsi:445 */
		};

		/* node '/soc/pwm@40021000' defined in zephyr/dts/arm/nordic/nrf52840.dtsi:448 */
		pwm1: pwm@40021000 {
			compatible = "nordic,nrf-pwm"; /* in zephyr/dts/arm/nordic/nrf52840.dtsi:449 */
			reg = < 0x40021000 0x1000 >;   /* in zephyr/dts/arm/nordic/nrf52840.dtsi:450 */
			interrupts = < 0x21 0x1 >;     /* in zephyr/dts/arm/nordic/nrf52840.dtsi:451 */
			status = "disabled";           /* in zephyr/dts/arm/nordic/nrf52840.dtsi:452 */
			#pwm-cells = < 0x3 >;          /* in zephyr/dts/arm/nordic/nrf52840.dtsi:453 */
		};

		/* node '/soc/pwm@40022000' defined in zephyr/dts/arm/nordic/nrf52840.dtsi:456 */
		pwm2: pwm@40022000 {
			compatible = "nordic,nrf-pwm"; /* in zephyr/dts/arm/nordic/nrf52840.dtsi:457 */
			reg = < 0x40022000 0x1000 >;   /* in zephyr/dts/arm/nordic/nrf52840.dtsi:458 */
			interrupts = < 0x22 0x1 >;     /* in zephyr/dts/arm/nordic/nrf52840.dtsi:459 */
			status = "disabled";           /* in zephyr/dts/arm/nordic/nrf52840.dtsi:460 */
			#pwm-cells = < 0x3 >;          /* in zephyr/dts/arm/nordic/nrf52840.dtsi:461 */
		};

		/* node '/soc/spi@40023000' defined in zephyr/dts/arm/nordic/nrf52840.dtsi:464 */
		spi2: spi@40023000 {
			#address-cells = < 0x1 >;       /* in zephyr/dts/arm/nordic/nrf52840.dtsi:473 */
			#size-cells = < 0x0 >;          /* in zephyr/dts/arm/nordic/nrf52840.dtsi:474 */
			reg = < 0x40023000 0x1000 >;    /* in zephyr/dts/arm/nordic/nrf52840.dtsi:475 */
			interrupts = < 0x23 0x1 >;      /* in zephyr/dts/arm/nordic/nrf52840.dtsi:476 */
			max-frequency = < 0x7a1200 >;   /* in zephyr/dts/arm/nordic/nrf52840.dtsi:477 */
			easydma-maxcnt-bits = < 0x10 >; /* in zephyr/dts/arm/nordic/nrf52840.dtsi:478 */
			status = "okay";                /* in ../../Documents/watch_project/nrf_firmware/boards/sw/ninab306/ninab306.dts:167 */
			pinctrl-0 = < &spi2_default >;  /* in ../../Documents/watch_project/nrf_firmware/boards/sw/ninab306/ninab306.dts:168 */
			pinctrl-1 = < &spi2_sleep >;    /* in ../../Documents/watch_project/nrf_firmware/boards/sw/ninab306/ninab306.dts:169 */
			pinctrl-names = "default",
			                "sleep";        /* in ../../Documents/watch_project/nrf_firmware/boards/sw/ninab306/ninab306.dts:170 */
			cs-gpios = < &gpio0 0x1d 0x0 >; /* in ../../Documents/watch_project/nrf_firmware/boards/sw/ninab306/ninab306.dts:171 */
			compatible = "nordic,nrf-spi";  /* in ../../Documents/watch_project/nrf_firmware/boards/sw/ninab306/ninab306.dts:172 */
			phandle = < 0x9 >;              /* in ../../Documents/watch_project/firmware/ninab306_nrf52840.overlay:26 */
		};

		/* node '/soc/rtc@40024000' defined in zephyr/dts/arm/nordic/nrf52840.dtsi:482 */
		rtc2: rtc@40024000 {
			compatible = "nordic,nrf-rtc"; /* in zephyr/dts/arm/nordic/nrf52840.dtsi:483 */
			reg = < 0x40024000 0x1000 >;   /* in zephyr/dts/arm/nordic/nrf52840.dtsi:484 */
			cc-num = < 0x4 >;              /* in zephyr/dts/arm/nordic/nrf52840.dtsi:485 */
			interrupts = < 0x24 0x1 >;     /* in zephyr/dts/arm/nordic/nrf52840.dtsi:486 */
			status = "disabled";           /* in zephyr/dts/arm/nordic/nrf52840.dtsi:487 */
			clock-frequency = < 0x8000 >;  /* in zephyr/dts/arm/nordic/nrf52840.dtsi:488 */
			prescaler = < 0x1 >;           /* in zephyr/dts/arm/nordic/nrf52840.dtsi:489 */
		};

		/* node '/soc/i2s@40025000' defined in zephyr/dts/arm/nordic/nrf52840.dtsi:492 */
		i2s0: i2s@40025000 {
			compatible = "nordic,nrf-i2s"; /* in zephyr/dts/arm/nordic/nrf52840.dtsi:493 */
			#address-cells = < 0x1 >;      /* in zephyr/dts/arm/nordic/nrf52840.dtsi:494 */
			#size-cells = < 0x0 >;         /* in zephyr/dts/arm/nordic/nrf52840.dtsi:495 */
			reg = < 0x40025000 0x1000 >;   /* in zephyr/dts/arm/nordic/nrf52840.dtsi:496 */
			interrupts = < 0x25 0x1 >;     /* in zephyr/dts/arm/nordic/nrf52840.dtsi:497 */
			status = "disabled";           /* in zephyr/dts/arm/nordic/nrf52840.dtsi:498 */
		};

		/* node '/soc/usbd@40027000' defined in zephyr/dts/arm/nordic/nrf52840.dtsi:501 */
		usbd: usbd@40027000 {
			compatible = "nordic,nrf-usbd"; /* in zephyr/dts/arm/nordic/nrf52840.dtsi:502 */
			reg = < 0x40027000 0x1000 >;    /* in zephyr/dts/arm/nordic/nrf52840.dtsi:503 */
			interrupts = < 0x27 0x1 >;      /* in zephyr/dts/arm/nordic/nrf52840.dtsi:504 */
			num-bidir-endpoints = < 0x1 >;  /* in zephyr/dts/arm/nordic/nrf52840.dtsi:505 */
			num-in-endpoints = < 0x7 >;     /* in zephyr/dts/arm/nordic/nrf52840.dtsi:506 */
			num-out-endpoints = < 0x7 >;    /* in zephyr/dts/arm/nordic/nrf52840.dtsi:507 */
			num-isoin-endpoints = < 0x1 >;  /* in zephyr/dts/arm/nordic/nrf52840.dtsi:508 */
			num-isoout-endpoints = < 0x1 >; /* in zephyr/dts/arm/nordic/nrf52840.dtsi:509 */
			status = "okay";                /* in ../../Documents/watch_project/nrf_firmware/boards/sw/ninab306/ninab306.dts:160 */

			/* node '/soc/usbd@40027000/cdc_acm_uart0' defined in ../../Documents/watch_project/nrf_firmware/boards/sw/ninab306/ninab306.dts:161 */
			cdc_acm_uart0: cdc_acm_uart0 {
				compatible = "zephyr,cdc-acm-uart"; /* in ../../Documents/watch_project/nrf_firmware/boards/sw/ninab306/ninab306.dts:162 */
			};
		};

		/* node '/soc/uart@40028000' defined in zephyr/dts/arm/nordic/nrf52840.dtsi:513 */
		uart1: uart@40028000 {
			compatible = "nordic,nrf-uarte"; /* in zephyr/dts/arm/nordic/nrf52840.dtsi:514 */
			reg = < 0x40028000 0x1000 >;     /* in zephyr/dts/arm/nordic/nrf52840.dtsi:515 */
			interrupts = < 0x28 0x1 >;       /* in zephyr/dts/arm/nordic/nrf52840.dtsi:516 */
			status = "disabled";             /* in zephyr/dts/arm/nordic/nrf52840.dtsi:517 */
		};

		/* node '/soc/qspi@40029000' defined in zephyr/dts/arm/nordic/nrf52840.dtsi:520 */
		qspi: qspi@40029000 {
			compatible = "nordic,nrf-qspi"; /* in zephyr/dts/arm/nordic/nrf52840.dtsi:521 */
			#address-cells = < 0x1 >;       /* in zephyr/dts/arm/nordic/nrf52840.dtsi:522 */
			#size-cells = < 0x0 >;          /* in zephyr/dts/arm/nordic/nrf52840.dtsi:523 */
			reg = < 0x40029000 0x1000 >,
			      < 0x12000000 0x8000000 >; /* in zephyr/dts/arm/nordic/nrf52840.dtsi:524 */
			reg-names = "qspi",
			            "qspi_mm";          /* in zephyr/dts/arm/nordic/nrf52840.dtsi:525 */
			interrupts = < 0x29 0x1 >;      /* in zephyr/dts/arm/nordic/nrf52840.dtsi:526 */
			status = "disabled";            /* in zephyr/dts/arm/nordic/nrf52840.dtsi:527 */
		};

		/* node '/soc/pwm@4002d000' defined in zephyr/dts/arm/nordic/nrf52840.dtsi:530 */
		pwm3: pwm@4002d000 {
			compatible = "nordic,nrf-pwm"; /* in zephyr/dts/arm/nordic/nrf52840.dtsi:531 */
			reg = < 0x4002d000 0x1000 >;   /* in zephyr/dts/arm/nordic/nrf52840.dtsi:532 */
			interrupts = < 0x2d 0x1 >;     /* in zephyr/dts/arm/nordic/nrf52840.dtsi:533 */
			status = "disabled";           /* in zephyr/dts/arm/nordic/nrf52840.dtsi:534 */
			#pwm-cells = < 0x3 >;          /* in zephyr/dts/arm/nordic/nrf52840.dtsi:535 */
		};

		/* node '/soc/spi@4002f000' defined in zephyr/dts/arm/nordic/nrf52840.dtsi:538 */
		spi3: spi@4002f000 {
			compatible = "nordic,nrf-spim"; /* in zephyr/dts/arm/nordic/nrf52840.dtsi:539 */
			#address-cells = < 0x1 >;       /* in zephyr/dts/arm/nordic/nrf52840.dtsi:540 */
			#size-cells = < 0x0 >;          /* in zephyr/dts/arm/nordic/nrf52840.dtsi:541 */
			reg = < 0x4002f000 0x1000 >;    /* in zephyr/dts/arm/nordic/nrf52840.dtsi:542 */
			interrupts = < 0x2f 0x1 >;      /* in zephyr/dts/arm/nordic/nrf52840.dtsi:543 */
			max-frequency = < 0x1e84800 >;  /* in zephyr/dts/arm/nordic/nrf52840.dtsi:544 */
			easydma-maxcnt-bits = < 0x10 >; /* in zephyr/dts/arm/nordic/nrf52840.dtsi:545 */
			rx-delay-supported;             /* in zephyr/dts/arm/nordic/nrf52840.dtsi:546 */
			rx-delay = < 0x2 >;             /* in zephyr/dts/arm/nordic/nrf52840.dtsi:547 */
			status = "disabled";            /* in zephyr/dts/arm/nordic/nrf52840.dtsi:548 */
		};

		/* node '/soc/gpio@50000000' defined in zephyr/dts/arm/nordic/nrf52840.dtsi:551 */
		gpio0: gpio@50000000 {
			compatible = "nordic,nrf-gpio";              /* in zephyr/dts/arm/nordic/nrf52840.dtsi:552 */
			gpio-controller;                             /* in zephyr/dts/arm/nordic/nrf52840.dtsi:553 */
			reg = < 0x50000000 0x200 0x50000500 0x300 >; /* in zephyr/dts/arm/nordic/nrf52840.dtsi:554 */
			#gpio-cells = < 0x2 >;                       /* in zephyr/dts/arm/nordic/nrf52840.dtsi:556 */
			port = < 0x0 >;                              /* in zephyr/dts/arm/nordic/nrf52840.dtsi:558 */
			gpiote-instance = < &gpiote >;               /* in zephyr/dts/arm/nordic/nrf52840.dtsi:559 */
			status = "okay";                             /* in ../../Documents/watch_project/nrf_firmware/boards/sw/ninab306/ninab306.dts:147 */
			phandle = < 0x4 >;                           /* in ../../Documents/watch_project/nrf_firmware/boards/sw/ninab306/ninab306.dts:120 */
		};

		/* node '/soc/gpio@50000300' defined in zephyr/dts/arm/nordic/nrf52840.dtsi:562 */
		gpio1: gpio@50000300 {
			compatible = "nordic,nrf-gpio";              /* in zephyr/dts/arm/nordic/nrf52840.dtsi:563 */
			gpio-controller;                             /* in zephyr/dts/arm/nordic/nrf52840.dtsi:564 */
			reg = < 0x50000300 0x200 0x50000800 0x300 >; /* in zephyr/dts/arm/nordic/nrf52840.dtsi:565 */
			#gpio-cells = < 0x2 >;                       /* in zephyr/dts/arm/nordic/nrf52840.dtsi:567 */
			ngpios = < 0x10 >;                           /* in zephyr/dts/arm/nordic/nrf52840.dtsi:568 */
			port = < 0x1 >;                              /* in zephyr/dts/arm/nordic/nrf52840.dtsi:570 */
			gpiote-instance = < &gpiote >;               /* in zephyr/dts/arm/nordic/nrf52840.dtsi:571 */
			status = "okay";                             /* in ../../Documents/watch_project/nrf_firmware/boards/sw/ninab306/ninab306.dts:155 */
		};

		/* node '/soc/crypto@5002a000' defined in zephyr/dts/arm/nordic/nrf52840.dtsi:574 */
		cryptocell: crypto@5002a000 {
			compatible = "arm,cryptocell-310"; /* in zephyr/dts/arm/nordic/nrf52840.dtsi:575 */
			reg = < 0x5002a000 0x1000 >,
			      < 0x5002b000 0x1000 >;       /* in zephyr/dts/arm/nordic/nrf52840.dtsi:576 */
			reg-names = "wrapper",
			            "core";                /* in zephyr/dts/arm/nordic/nrf52840.dtsi:577 */
			interrupts = < 0x2a 0x1 >;         /* in zephyr/dts/arm/nordic/nrf52840.dtsi:578 */
			status = "okay";                   /* in zephyr/dts/arm/nordic/nrf52840.dtsi:579 */
		};
	};

	/* node '/pin-controller' defined in zephyr/dts/vendor/nordic/nrf_common.dtsi:26 */
	pinctrl: pin-controller {
		compatible = "nordic,nrf-pinctrl"; /* in zephyr/dts/vendor/nordic/nrf_common.dtsi:31 */

		/* node '/pin-controller/i2c0_default' defined in ../../Documents/watch_project/nrf_firmware/boards/sw/ninab306/ninab306.dts:176 */
		i2c0_default: i2c0_default {
			phandle = < 0x2 >; /* in ../../Documents/watch_project/nrf_firmware/boards/sw/ninab306/ninab306.dts:67 */

			/* node '/pin-controller/i2c0_default/group1' defined in ../../Documents/watch_project/nrf_firmware/boards/sw/ninab306/ninab306.dts:177 */
			group1 {
				psels = < 0xb000015 >,
				        < 0xc000016 >; /* in ../../Documents/watch_project/nrf_firmware/boards/sw/ninab306/ninab306.dts:178 */
			};
		};

		/* node '/pin-controller/i2c0_sleep' defined in ../../Documents/watch_project/nrf_firmware/boards/sw/ninab306/ninab306.dts:182 */
		i2c0_sleep: i2c0_sleep {
			phandle = < 0x3 >; /* in ../../Documents/watch_project/nrf_firmware/boards/sw/ninab306/ninab306.dts:68 */

			/* node '/pin-controller/i2c0_sleep/group1' defined in ../../Documents/watch_project/nrf_firmware/boards/sw/ninab306/ninab306.dts:183 */
			group1 {
				psels = < 0xb000015 >; /* in ../../Documents/watch_project/nrf_firmware/boards/sw/ninab306/ninab306.dts:184 */
			};
		};

		/* node '/pin-controller/spi2_default' defined in ../../Documents/watch_project/nrf_firmware/boards/sw/ninab306/ninab306.dts:188 */
		spi2_default: spi2_default {
			phandle = < 0x5 >; /* in ../../Documents/watch_project/nrf_firmware/boards/sw/ninab306/ninab306.dts:168 */

			/* node '/pin-controller/spi2_default/group1' defined in ../../Documents/watch_project/nrf_firmware/boards/sw/ninab306/ninab306.dts:189 */
			group1 {
				psels = < 0x500002c >,
				        < 0x400002d >,
				        < 0x600000e >; /* in ../../Documents/watch_project/nrf_firmware/boards/sw/ninab306/ninab306.dts:190 */
			};
		};

		/* node '/pin-controller/spi2_sleep' defined in ../../Documents/watch_project/nrf_firmware/boards/sw/ninab306/ninab306.dts:196 */
		spi2_sleep: spi2_sleep {
			phandle = < 0x6 >; /* in ../../Documents/watch_project/nrf_firmware/boards/sw/ninab306/ninab306.dts:169 */
		};
	};

	/* node '/entropy_bt_hci' defined in zephyr/dts/vendor/nordic/nrf_common.dtsi:34 */
	rng_hci: entropy_bt_hci {
		compatible = "zephyr,bt-hci-entropy"; /* in zephyr/dts/vendor/nordic/nrf_common.dtsi:35 */
		status = "disabled";                  /* in zephyr/dts/vendor/nordic/nrf_common.dtsi:36 */
	};

	/* node '/sw-pwm' defined in zephyr/dts/vendor/nordic/nrf_common.dtsi:39 */
	sw_pwm: sw-pwm {
		compatible = "nordic,nrf-sw-pwm"; /* in zephyr/dts/vendor/nordic/nrf_common.dtsi:40 */
		status = "disabled";              /* in zephyr/dts/vendor/nordic/nrf_common.dtsi:41 */
		generator = < &timer1 >;          /* in zephyr/dts/vendor/nordic/nrf_common.dtsi:42 */
		clock-prescaler = < 0x0 >;        /* in zephyr/dts/vendor/nordic/nrf_common.dtsi:43 */
		#pwm-cells = < 0x3 >;             /* in zephyr/dts/vendor/nordic/nrf_common.dtsi:44 */
	};

	/* node '/cpus' defined in zephyr/dts/arm/nordic/nrf52840.dtsi:19 */
	cpus {
		#address-cells = < 0x1 >; /* in zephyr/dts/arm/nordic/nrf52840.dtsi:20 */
		#size-cells = < 0x0 >;    /* in zephyr/dts/arm/nordic/nrf52840.dtsi:21 */

		/* node '/cpus/cpu@0' defined in zephyr/dts/arm/nordic/nrf52840.dtsi:23 */
		cpu@0 {
			device_type = "cpu";           /* in zephyr/dts/arm/nordic/nrf52840.dtsi:24 */
			compatible = "arm,cortex-m4f"; /* in zephyr/dts/arm/nordic/nrf52840.dtsi:25 */
			reg = < 0x0 >;                 /* in zephyr/dts/arm/nordic/nrf52840.dtsi:26 */
			#address-cells = < 0x1 >;      /* in zephyr/dts/arm/nordic/nrf52840.dtsi:27 */
			#size-cells = < 0x1 >;         /* in zephyr/dts/arm/nordic/nrf52840.dtsi:28 */

			/* node '/cpus/cpu@0/itm@e0000000' defined in zephyr/dts/arm/nordic/nrf52840.dtsi:30 */
			itm: itm@e0000000 {
				compatible = "arm,armv7m-itm";     /* in zephyr/dts/arm/nordic/nrf52840.dtsi:31 */
				reg = < 0xe0000000 0x1000 >;       /* in zephyr/dts/arm/nordic/nrf52840.dtsi:32 */
				swo-ref-frequency = < 0x1e84800 >; /* in zephyr/dts/arm/nordic/nrf52840.dtsi:33 */
			};
		};
	};

	/* node '/clocks' defined in zephyr/dts/arm/nordic/nrf52840.dtsi:38 */
	clocks {

		/* node '/clocks/hfxo' defined in zephyr/dts/arm/nordic/nrf52840.dtsi:39 */
		hfxo: hfxo {
			compatible = "nordic,nrf52-hfxo"; /* in zephyr/dts/arm/nordic/nrf52840.dtsi:40 */
			clock-frequency = < 0x3d09000 >;  /* in zephyr/dts/arm/nordic/nrf52840.dtsi:41 */
			startup-time-us = < 0x578 >;      /* in zephyr/dts/arm/nordic/nrf52840.dtsi:42 */
			#clock-cells = < 0x0 >;           /* in zephyr/dts/arm/nordic/nrf52840.dtsi:43 */
		};
	};

	/* node '/buttons' defined in ../../Documents/watch_project/nrf_firmware/boards/sw/ninab306/ninab306.dts:18 */
	buttons {
		compatible = "gpio-keys"; /* in ../../Documents/watch_project/nrf_firmware/boards/sw/ninab306/ninab306.dts:19 */

		/* node '/buttons/button_0' defined in ../../Documents/watch_project/nrf_firmware/boards/sw/ninab306/ninab306.dts:20 */
		button0: button_0 {
			label = "navigation button"; /* in ../../Documents/watch_project/nrf_firmware/boards/sw/ninab306/ninab306.dts:21 */
			gpios = < &gpio0 0x10 0x0 >; /* in ../../Documents/watch_project/nrf_firmware/boards/sw/ninab306/ninab306.dts:22 */
		};

		/* node '/buttons/button_1' defined in ../../Documents/watch_project/nrf_firmware/boards/sw/ninab306/ninab306.dts:25 */
		button1: button_1 {
			label = "tft_backlight button"; /* in ../../Documents/watch_project/nrf_firmware/boards/sw/ninab306/ninab306.dts:26 */
			gpios = < &gpio0 0xf 0x0 >;     /* in ../../Documents/watch_project/nrf_firmware/boards/sw/ninab306/ninab306.dts:27 */
		};

		/* node '/buttons/button_2' defined in ../../Documents/watch_project/firmware/ninab306_nrf52840.overlay:43 */
		button2: button_2 {
			label = "rtcc clkoe button";   /* in ../../Documents/watch_project/firmware/ninab306_nrf52840.overlay:44 */
			gpios = < &gpio0 0x1f 0x200 >; /* in ../../Documents/watch_project/firmware/ninab306_nrf52840.overlay:45 */
		};
	};

	/* node '/mipi_dbi' defined in ../../Documents/watch_project/firmware/ninab306_nrf52840.overlay:21 */
	mipi_dbi {
		compatible = "zephyr,mipi-dbi-spi"; /* in ../../Documents/watch_project/firmware/ninab306_nrf52840.overlay:22 */
		status = "okay";                    /* in ../../Documents/watch_project/firmware/ninab306_nrf52840.overlay:23 */
		reset-gpios = < &gpio0 0x12 0x0 >;  /* in ../../Documents/watch_project/firmware/ninab306_nrf52840.overlay:24 */
		dc-gpios = < &gpio0 0x1e 0x0 >;     /* in ../../Documents/watch_project/firmware/ninab306_nrf52840.overlay:25 */
		spi-dev = < &spi2 >;                /* in ../../Documents/watch_project/firmware/ninab306_nrf52840.overlay:26 */
		write-only;                         /* in ../../Documents/watch_project/firmware/ninab306_nrf52840.overlay:27 */
		#address-cells = < 0x1 >;           /* in ../../Documents/watch_project/firmware/ninab306_nrf52840.overlay:28 */
		#size-cells = < 0x0 >;              /* in ../../Documents/watch_project/firmware/ninab306_nrf52840.overlay:29 */

		/* node '/mipi_dbi/gc9a01@0' defined in ../../Documents/watch_project/firmware/ninab306_nrf52840.overlay:31 */
		gc9a01: gc9a01@0 {
			status = "okay";                    /* in ../../Documents/watch_project/firmware/ninab306_nrf52840.overlay:32 */
			compatible = "galaxycore,gc9x01x";  /* in ../../Documents/watch_project/firmware/ninab306_nrf52840.overlay:33 */
			reg = < 0x0 >;                      /* in ../../Documents/watch_project/firmware/ninab306_nrf52840.overlay:34 */
			mipi-max-frequency = < 0x5f5e100 >; /* in ../../Documents/watch_project/firmware/ninab306_nrf52840.overlay:35 */
			pixel-format = < 0x10 >;            /* in ../../Documents/watch_project/firmware/ninab306_nrf52840.overlay:36 */
			width = < 0xf0 >;                   /* in ../../Documents/watch_project/firmware/ninab306_nrf52840.overlay:37 */
			height = < 0xf0 >;                  /* in ../../Documents/watch_project/firmware/ninab306_nrf52840.overlay:38 */
		};
	};
};
